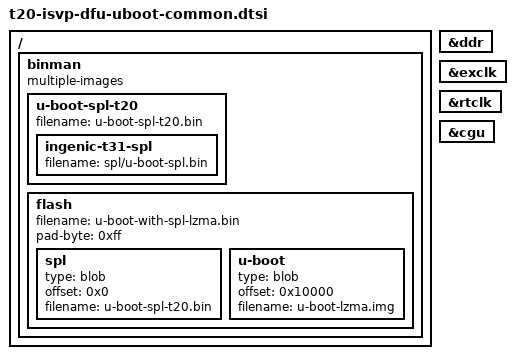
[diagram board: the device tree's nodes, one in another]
// SPDX-License-Identifier: GPL-2.0+
/*
 * Shared U-Boot overlay for the Ingenic ISVP-T20 DFU/USB-boot leaf DTs.
 * Each per-SKU <leaf>-u-boot.dtsi is a one-line include of this file.
 *
 * The USB-boot path uploads spl/u-boot-spl.bin + u-boot-lzma.img via the
 * mask ROM (the XBurst1-generic t31-usbboot protocol), so the binman
 * flash image here is not used in the USB-boot flow; it is kept for a
 * sensible `make` artifact.
 *
 * USB-boot is a TPL chain: the mask ROM uploads the cache-as-RAM TPL, whose
 * only DM device is the DDR controller (its probe brings up PLL + DDR), then
 * the TPL returns into the ROM's USB loop and the ROM uploads U-Boot proper to
 * DRAM. So &ddr is the only node tagged for the TPL phase (bootph-all);
 * everything else is bootph-pre-ram + bootph-some-ram (present pre-relocation
 * in U-Boot proper, absent from the minimal TPL). See the matching note in
 * t20-isvp-uboot-common.dtsi.
 */

/ {
	binman: binman {
		multiple-images;
	};
};

&binman {
	u-boot-spl-t20 {
		filename = "u-boot-spl-t20.bin";

		ingenic-t31-spl {
			filename = "spl/u-boot-spl.bin";
		};
	};

	flash {
		filename = "u-boot-with-spl-lzma.bin";
		pad-byte = <0xff>;

		spl {
			type = "blob";
			offset = <0x0>;
			filename = "u-boot-spl-t20.bin";
		};

		u-boot {
			type = "blob";
			offset = <0x10000>;
			filename = "u-boot-lzma.img";
		};
	};
};

&ddr { bootph-all; };		/* per-SKU compatible set by the leaf .dts */

&exclk { bootph-pre-ram; bootph-some-ram; };
&rtclk { bootph-pre-ram; bootph-some-ram; };
&cgu { bootph-pre-ram; bootph-some-ram; };
